AUTOSAR XML (schema 314)
package /ComponentType
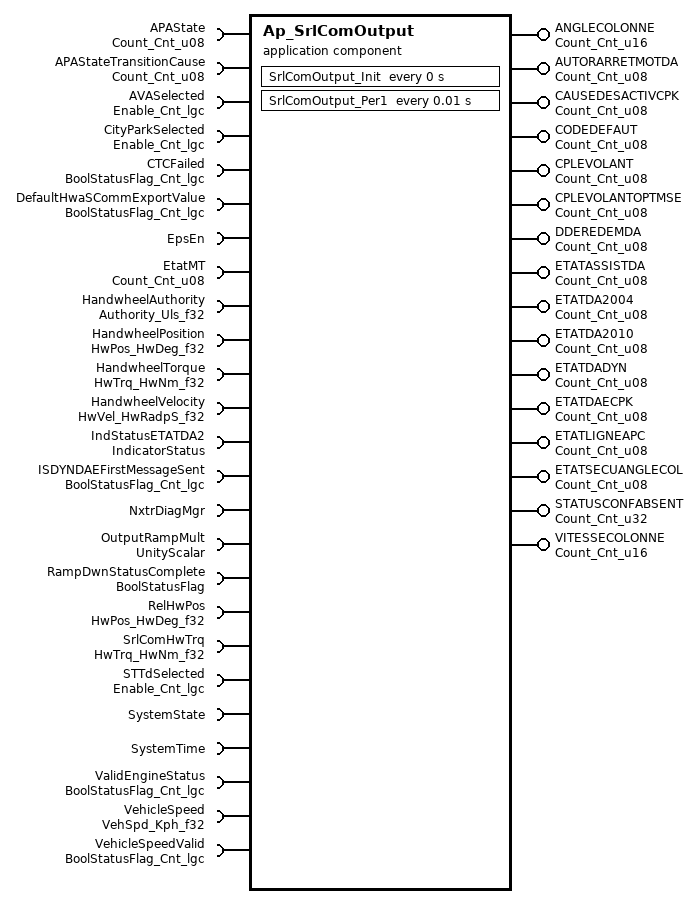
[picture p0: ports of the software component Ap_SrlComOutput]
  application software component type Ap_SrlComOutput
    16 x provide port:
      ANGLECOLONNE: unqueued-sender-com-spec{data-element=Cnt_u16, can-invalidate=false, init-value=D_ZERO_CNT_U16}, provided-interface=Count_Cnt_u16
      AUTORARRETMOTDA: unqueued-sender-com-spec{data-element=Cnt_u08, can-invalidate=false, init-value=D_ZERO_CNT_U8}, provided-interface=Count_Cnt_u08
      CAUSEDESACTIVCPK: unqueued-sender-com-spec{data-element=Cnt_u08, can-invalidate=false, init-value=D_ZERO_CNT_U8}, provided-interface=Count_Cnt_u08
      CODEDEFAUT: unqueued-sender-com-spec{data-element=Cnt_u08, can-invalidate=false, init-value=D_ZERO_CNT_U8}, provided-interface=Count_Cnt_u08
      CPLEVOLANT: unqueued-sender-com-spec{data-element=Cnt_u08, can-invalidate=false, init-value=D_ZERO_CNT_U8}, provided-interface=Count_Cnt_u08
      CPLEVOLANTOPTMSE: unqueued-sender-com-spec{data-element=Cnt_u08, can-invalidate=false, init-value=D_ZERO_CNT_U8}, provided-interface=Count_Cnt_u08
      DDEREDEMDA: unqueued-sender-com-spec{data-element=Cnt_u08, can-invalidate=false, init-value=D_ZERO_CNT_U8}, provided-interface=Count_Cnt_u08
      ETATASSISTDA: unqueued-sender-com-spec{data-element=Cnt_u08, can-invalidate=false, init-value=D_ZERO_CNT_U8}, provided-interface=Count_Cnt_u08
      ETATDA2004: unqueued-sender-com-spec{data-element=Cnt_u08, can-invalidate=false, init-value=D_ZERO_CNT_U8}, provided-interface=Count_Cnt_u08
      ETATDA2010: unqueued-sender-com-spec{data-element=Cnt_u08, can-invalidate=false, init-value=D_ZERO_CNT_U8}, provided-interface=Count_Cnt_u08
      ETATDADYN: unqueued-sender-com-spec{data-element=Cnt_u08, can-invalidate=false, init-value=D_ZERO_CNT_U8}, provided-interface=Count_Cnt_u08
      ETATDAECPK: unqueued-sender-com-spec{data-element=Cnt_u08, can-invalidate=false, init-value=D_ZERO_CNT_U8}, provided-interface=Count_Cnt_u08
      ETATLIGNEAPC: unqueued-sender-com-spec{data-element=Cnt_u08, can-invalidate=false, init-value=D_ZERO_CNT_U8}, provided-interface=Count_Cnt_u08
      ETATSECUANGLECOL: unqueued-sender-com-spec{data-element=Cnt_u08, can-invalidate=false, init-value=D_ZERO_CNT_U8}, provided-interface=Count_Cnt_u08
      STATUSCONFABSENT: unqueued-sender-com-spec{data-element=Cnt_u32, can-invalidate=false, init-value=D_ZERO_CNT_U32}, provided-interface=Count_Cnt_u32
      VITESSECOLONNE: unqueued-sender-com-spec{data-element=Cnt_u16, can-invalidate=false, init-value=D_ZERO_CNT_U16}, provided-interface=Count_Cnt_u16
    25 x require port:
      APAState: unqueued-receiver-com-spec{data-element=Cnt_u08, init-value=D_ZERO_CNT_U8}, required-interface=Count_Cnt_u08
      APAStateTransitionCause: unqueued-receiver-com-spec{data-element=Cnt_u08, init-value=D_ZERO_CNT_U8}, required-interface=Count_Cnt_u08
      AVASelected: unqueued-receiver-com-spec{data-element=Cnt_lgc, init-value=D_FALSE_CNT_LGC}, required-interface=Enable_Cnt_lgc
      CityParkSelected: unqueued-receiver-com-spec{data-element=Cnt_lgc, init-value=D_FALSE_CNT_LGC}, required-interface=Enable_Cnt_lgc
      CTCFailed: unqueued-receiver-com-spec{data-element=Cnt_lgc, init-value=D_FALSE_CNT_LGC}, required-interface=BoolStatusFlag_Cnt_lgc
      DefaultHwaSCommExportValue: unqueued-receiver-com-spec{data-element=Cnt_lgc, init-value=D_FALSE_CNT_LGC}, required-interface=BoolStatusFlag_Cnt_lgc
      EpsEn: client-com-spec=OP_GET, required-interface=EpsEn
      EtatMT: unqueued-receiver-com-spec{data-element=Cnt_u08, init-value=D_ZERO_CNT_U8}, required-interface=Count_Cnt_u08
      HandwheelAuthority: unqueued-receiver-com-spec{data-element=Uls_f32, init-value=D_ZERO_ULS_F32}, required-interface=Authority_Uls_f32
      HandwheelPosition: unqueued-receiver-com-spec{data-element=HwDeg_f32, init-value=D_ZERO_ULS_F32}, required-interface=HwPos_HwDeg_f32
      HandwheelTorque: unqueued-receiver-com-spec{data-element=HwNm_f32, init-value=D_ZERO_ULS_F32}, required-interface=HwTrq_HwNm_f32
      HandwheelVelocity: unqueued-receiver-com-spec{data-element=HwRadpS_f32, init-value=D_ZERO_ULS_F32}, required-interface=HwVel_HwRadpS_f32
      IndStatusETATDA2: client-com-spec=GetIndicatorStatus, required-interface=IndicatorStatus
      ISDYNDAEFirstMessageSent: unqueued-receiver-com-spec{data-element=Cnt_lgc, init-value=D_FALSE_CNT_LGC}, required-interface=BoolStatusFlag_Cnt_lgc
      NxtrDiagMgr: required-com-specs=[GetNTCActive, GetNTCFailed, GetNTCStatus, SetNTCStatus], required-interface=NxtrDiagMgr
      OutputRampMult: unqueued-receiver-com-spec{data-element=Uls_f32, init-value=D_ZERO_ULS_F32}, required-interface=UnityScalar
      RampDwnStatusComplete: unqueued-receiver-com-spec{data-element=Cnt_lgc, init-value=D_FALSE_CNT_LGC}, required-interface=BoolStatusFlag
      RelHwPos: unqueued-receiver-com-spec{data-element=HwDeg_f32, init-value=D_ZERO_ULS_F32}, required-interface=HwPos_HwDeg_f32
      SrlComHwTrq: unqueued-receiver-com-spec{data-element=HwNm_f32, init-value=D_ZERO_ULS_F32}, required-interface=HwTrq_HwNm_f32
      STTdSelected: unqueued-receiver-com-spec{data-element=Cnt_lgc, init-value=D_FALSE_CNT_LGC}, required-interface=Enable_Cnt_lgc
      SystemState: required-interface=SystemState
      SystemTime: required-interface=SystemTime
        required-com-specs:
          DtrmnElapsedTime_mS_u16
          DtrmnElapsedTime_mS_u32
          DtrmnElapsedTime_uS_u16
          DtrmnElapsedTime_uS_u32
          GetSystemTime_mS_u32
          GetSystemTime_uS_u32
      ValidEngineStatus: unqueued-receiver-com-spec{data-element=Cnt_lgc, init-value=D_FALSE_CNT_LGC}, required-interface=BoolStatusFlag_Cnt_lgc
      VehicleSpeed: unqueued-receiver-com-spec{data-element=Kph_f32, init-value=D_ZERO_ULS_F32}, required-interface=VehSpd_Kph_f32
      VehicleSpeedValid: unqueued-receiver-com-spec{data-element=Cnt_lgc, init-value=D_FALSE_CNT_LGC}, required-interface=BoolStatusFlag_Cnt_lgc
  internal behavior Ap_SrlComOutput_InternalBehavior: component=Ap_SrlComOutput
    timing event SrlComOutput_InitEvent: start-on-event=SrlComOutput_Init, period=0
    timing event TMT_SrlComOutput_Per1: mode-dependency=dependent-on-mode=SystemState.Mode.OFF, start-on-event=SrlComOutput_Per1, period=0.01
    port-api-options:
      enable-take-address=false, indirect-api=false, port=ANGLECOLONNE
      enable-take-address=false, indirect-api=false, port=APAState
      enable-take-address=false, indirect-api=false, port=APAStateTransitionCause
      enable-take-address=false, indirect-api=false, port=AUTORARRETMOTDA
      enable-take-address=false, indirect-api=false, port=AVASelected
      enable-take-address=false, indirect-api=false, port=CAUSEDESACTIVCPK
      enable-take-address=false, indirect-api=false, port=CityParkSelected
      enable-take-address=false, indirect-api=false, port=CODEDEFAUT
      enable-take-address=false, indirect-api=false, port=CPLEVOLANT
      enable-take-address=false, indirect-api=false, port=CPLEVOLANTOPTMSE
      enable-take-address=false, indirect-api=false, port=CTCFailed
      enable-take-address=false, indirect-api=false, port=DDEREDEMDA
      enable-take-address=false, indirect-api=false, port=DefaultHwaSCommExportValue
      enable-take-address=false, indirect-api=false, port=EpsEn
      enable-take-address=false, indirect-api=false, port=ETATASSISTDA
      enable-take-address=false, indirect-api=false, port=ETATDA2004
      enable-take-address=false, indirect-api=false, port=ETATDA2010
      enable-take-address=false, indirect-api=false, port=ETATDADYN
      enable-take-address=false, indirect-api=false, port=ETATDAECPK
      enable-take-address=false, indirect-api=false, port=ETATLIGNEAPC
      enable-take-address=false, indirect-api=false, port=EtatMT
      enable-take-address=false, indirect-api=false, port=ETATSECUANGLECOL
      enable-take-address=false, indirect-api=false, port=HandwheelAuthority
      enable-take-address=false, indirect-api=false, port=HandwheelPosition
      enable-take-address=false, indirect-api=false, port=HandwheelTorque
      enable-take-address=false, indirect-api=false, port=HandwheelVelocity
      enable-take-address=false, indirect-api=false, port=IndStatusETATDA2
      enable-take-address=false, indirect-api=false, port=ISDYNDAEFirstMessageSent
      enable-take-address=false, indirect-api=false, port=NxtrDiagMgr
      enable-take-address=false, indirect-api=false, port=OutputRampMult
      enable-take-address=false, indirect-api=false, port=RampDwnStatusComplete
      enable-take-address=false, indirect-api=false, port=RelHwPos
      enable-take-address=false, indirect-api=false, port=SrlComHwTrq
      enable-take-address=false, indirect-api=false, port=STATUSCONFABSENT
      enable-take-address=false, indirect-api=false, port=STTdSelected
      enable-take-address=false, indirect-api=false, port=SystemState
      enable-take-address=false, indirect-api=false, port=SystemTime
      enable-take-address=false, indirect-api=false, port=ValidEngineStatus
      enable-take-address=false, indirect-api=false, port=VehicleSpeed
      enable-take-address=false, indirect-api=false, port=VehicleSpeedValid
      enable-take-address=false, indirect-api=false, port=VITESSECOLONNE
    runnable SrlComOutput_Init
      sync call SC_SystemTime_GetSystemTime_mS_u32: operation=SystemTime.GetSystemTime_mS_u32, timeout=0
    runnable SrlComOutput_Per1
      20 x data read access:
        READ_APAState_Cnt_u08: data-element=APAState.Cnt_u08
        READ_APAStateTransitionCause_Cnt_u08: data-element=APAStateTransitionCause.Cnt_u08
        READ_AVASelected_Cnt_lgc: data-element=AVASelected.Cnt_lgc
        READ_CityParkSelected_Cnt_lgc: data-element=CityParkSelected.Cnt_lgc
        READ_CTCFailed_Cnt_lgc: data-element=CTCFailed.Cnt_lgc
        READ_DefaultHwaSCommExportValue_Cnt_lgc: data-element=DefaultHwaSCommExportValue.Cnt_lgc
        READ_EtatMT_Cnt_u08: data-element=EtatMT.Cnt_u08
        READ_HandwheelAuthority_Uls_f32: data-element=HandwheelAuthority.Uls_f32
        READ_HandwheelPosition_HwDeg_f32: data-element=HandwheelPosition.HwDeg_f32
        READ_HandwheelTorque_HwNm_f32: data-element=HandwheelTorque.HwNm_f32
        READ_HandwheelVelocity_HwRadpS_f32: data-element=HandwheelVelocity.HwRadpS_f32
        READ_ISDYNDAEFirstMessageSent_Cnt_lgc: data-element=ISDYNDAEFirstMessageSent.Cnt_lgc
        READ_OutputRampMult_Uls_f32: data-element=OutputRampMult.Uls_f32
        READ_RampDwnStatusComplete_Cnt_lgc: data-element=RampDwnStatusComplete.Cnt_lgc
        READ_RelHwPos_HwDeg_f32: data-element=RelHwPos.HwDeg_f32
        READ_SrlComHwTrq_HwNm_f32: data-element=SrlComHwTrq.HwNm_f32
        READ_STTdSelected_Cnt_lgc: data-element=STTdSelected.Cnt_lgc
        READ_ValidEngineStatus_Cnt_lgc: data-element=ValidEngineStatus.Cnt_lgc
        READ_VehicleSpeed_Kph_f32: data-element=VehicleSpeed.Kph_f32
        READ_VehicleSpeedValid_Cnt_lgc: data-element=VehicleSpeedValid.Cnt_lgc
      16 x data write access:
        WRITE_ANGLECOLONNE_Cnt_u16: data-element=ANGLECOLONNE.Cnt_u16
        WRITE_AUTORARRETMOTDA_Cnt_u08: data-element=AUTORARRETMOTDA.Cnt_u08
        WRITE_CAUSEDESACTIVCPK_Cnt_u08: data-element=CAUSEDESACTIVCPK.Cnt_u08
        WRITE_CODEDEFAUT_Cnt_u08: data-element=CODEDEFAUT.Cnt_u08
        WRITE_CPLEVOLANT_Cnt_u08: data-element=CPLEVOLANT.Cnt_u08
        WRITE_CPLEVOLANTOPTMSE_Cnt_u08: data-element=CPLEVOLANTOPTMSE.Cnt_u08
        WRITE_DDEREDEMDA_Cnt_u08: data-element=DDEREDEMDA.Cnt_u08
        WRITE_ETATASSISTDA_Cnt_u08: data-element=ETATASSISTDA.Cnt_u08
        WRITE_ETATDA2004_Cnt_u08: data-element=ETATDA2004.Cnt_u08
        WRITE_ETATDA2010_Cnt_u08: data-element=ETATDA2010.Cnt_u08
        WRITE_ETATDADYN_Cnt_u08: data-element=ETATDADYN.Cnt_u08
        WRITE_ETATDAECPK_Cnt_u08: data-element=ETATDAECPK.Cnt_u08
        WRITE_ETATLIGNEAPC_Cnt_u08: data-element=ETATLIGNEAPC.Cnt_u08
        WRITE_ETATSECUANGLECOL_Cnt_u08: data-element=ETATSECUANGLECOL.Cnt_u08
        WRITE_STATUSCONFABSENT_Cnt_u32: data-element=STATUSCONFABSENT.Cnt_u32
        WRITE_VITESSECOLONNE_Cnt_u16: data-element=VITESSECOLONNE.Cnt_u16
      5 x sync call, all with timeout=0:
        SC_EpsEn_OP_GET: operation=EpsEn.OP_GET
        SC_IndStatusETATDA2_GetIndicatorStatus: operation=IndStatusETATDA2.GetIndicatorStatus
        SC_NxtrDiagMgr_GetNTCFailed: operation=NxtrDiagMgr.GetNTCFailed
        SC_SystemTime_DtrmnElapsedTime_mS_u16: operation=SystemTime.DtrmnElapsedTime_mS_u16
        SC_SystemTime_GetSystemTime_mS_u32: operation=SystemTime.GetSystemTime_mS_u32
  swc implementation Ap_SrlComOutput_Implementation: behavior=Ap_SrlComOutput_InternalBehavior
    code-descriptors:
      code Code: type=SRC
